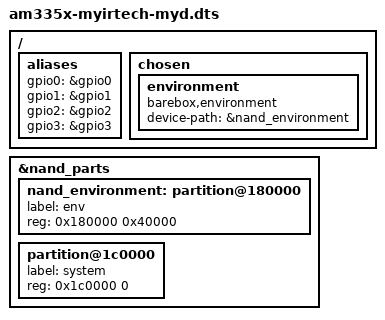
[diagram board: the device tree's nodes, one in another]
// SPDX-License-Identifier: GPL-2.0-or-later
/* SPDX-FileCopyrightText: Alexander Shiyan, <shc_work@mail.ru> */

/dts-v1/;

#include <arm/am335x-myirtech-myd.dts>

/ {
	aliases {
		gpio0 = &gpio0;
		gpio1 = &gpio1;
		gpio2 = &gpio2;
		gpio3 = &gpio3;
	};

	chosen {
		environment {
			compatible = "barebox,environment";
			device-path = &nand_environment;
		};
	};
};

&nand_parts {
	nand_environment: partition@180000 {
		label = "env";
		reg = <0x180000 0x40000>;
	};

	partition@1c0000 {
		label = "system";
		reg = <0x1c0000 0>;
	};
};
